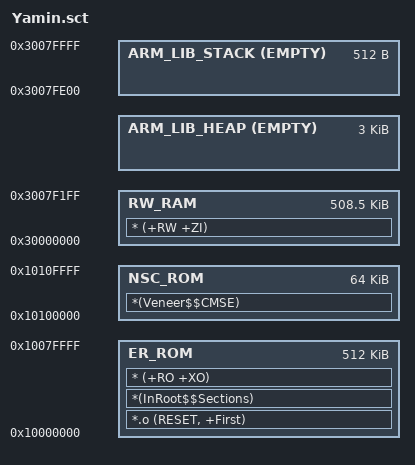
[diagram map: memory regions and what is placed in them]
#! armclang -E --target=arm-arm-none-eabi -march=armv8.1-m.main -xc
; command above MUST be in first line (no comment above!)

/*
 * Copyright (c) 2019 Arm Limited. All rights reserved.
 *
 * SPDX-License-Identifier: Apache-2.0
 *
 * Licensed under the Apache License, Version 2.0 (the License); you may
 * not use this file except in compliance with the License.
 * You may obtain a copy of the License at
 *
 * www.apache.org/licenses/LICENSE-2.0
 *
 * Unless required by applicable law or agreed to in writing, software
 * distributed under the License is distributed on an AS IS BASIS, WITHOUT
 * WARRANTIES OR CONDITIONS OF ANY KIND, either express or implied.
 * See the License for the specific language governing permissions and
 * limitations under the License.
 */

/*-----------------------------------------------------------------------------
 * File     Yamin.sct
 * Brief    AC6 Linker Script for Yamin Device (AN540)
 * Version  1.0.0
 *----------------------------------------------------------------------------*/

/*--------------------- Flash Configuration ----------------------------------*/
#if !defined (__USE_NONSECURE)
  #define __ROM_BASE     0x10000000
  #define __ROM_SIZE     0x00080000
#else
  #define __ROM_BASE     0x00080000
  #define __ROM_SIZE     0x00080000
#endif

/*--------------------- Embedded RAM Configuration ---------------------------*/
#if !defined (__USE_NONSECURE)
  #define __RAM_BASE     0x30000000
  #define __RAM_SIZE     0x00080000
#else
  #define __RAM_BASE     0x20080000
  #define __RAM_SIZE     0x00080000
#endif

/*--------------------- Non Secure Callable Configuration --------------------*/
#if !defined (__USE_NONSECURE)
  #define __NSC_BASE     0x10100000
  #define __NSC_SIZE     0x00010000
#endif

/*--------------------- Stack / Heap Configuration ---------------------------*/
#define __STACK_SIZE       0x00000200
#define __HEAP_SIZE        0x00000C00


/*----------------------------------------------------------------------------
  User Stack & Heap boundery definition
 *----------------------------------------------------------------------------*/
#define __STACK_TOP        (__RAM_BASE + __RAM_SIZE)      /* starts at end of RAM */
#define __HEAP_BASE        (AlignExpr(+0, 8))             /* starts after RW_RAM section, 8 byte aligned */
//#define __HEAP_BASE        (__RAM_BASE + __RAM_SIZE - __STACK_SIZE - __HEAP_SIZE)


/*----------------------------------------------------------------------------
  Scatter File Definitions definition
 *----------------------------------------------------------------------------*/
#define __RO_BASE         __ROM_BASE
#define __RO_SIZE         __ROM_SIZE

#define __RW_BASE        (__RAM_BASE        )
#define __RW_SIZE        (__RAM_SIZE - __STACK_SIZE - __HEAP_SIZE)



LR_ROM __RO_BASE __RO_SIZE  {                       ; load region size_region
  ER_ROM __RO_BASE __RO_SIZE  {                     ; load address = execution address
    *.o (RESET, +First)
    *(InRoot$$Sections)
    * (+RO +XO)
  }
  
  RW_RAM __RW_BASE __RW_SIZE  {                     ; RW data
    * (+RW +ZI)
  }

#if __HEAP_SIZE > 0
  ARM_LIB_HEAP  __HEAP_BASE EMPTY  __HEAP_SIZE  { ; Reserve empty region for heap
  }
#endif

  ARM_LIB_STACK __STACK_TOP EMPTY -__STACK_SIZE { ; Reserve empty region for stack 
  }
}

#if !defined (__USE_NONSECURE)
NSC_ROM __NSC_BASE __NSC_SIZE  {                    ; load region size_region
  NSC_ROM __NSC_BASE __NSC_SIZE  {                  ; load address = execution address
    *(Veneer$$CMSE)
  }
} 
#endif
